# PIC18F55Q24 register map
Vendor: Microchip
Registers are 8-bit, read-write, reset 0x0 unless marked. A register's access mark holds for its fields unless they carry their own. Addresses are absolute, and some are shared; only a register's first bit layout is shown; [hi:lo] are bit positions.

## DOS_xxxx_Interrupts
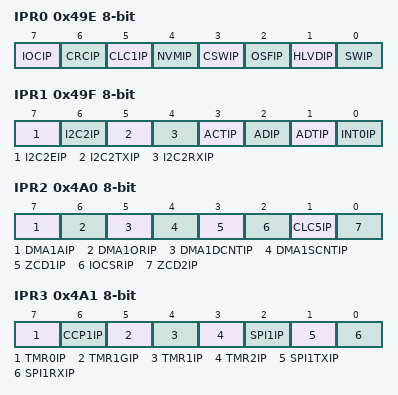
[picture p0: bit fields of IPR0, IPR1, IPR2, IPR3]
0x49E IPR0
  [7] IOCIP ro, [6] CRCIP, [5] CLC1IP, [4] NVMIP, [3] CSWIP, [2] OSFIP ro, [1] HLVDIP, [0] SWIP
0x49F IPR1
  [7] I2C2EIP, [6] I2C2IP, [5] I2C2TXIP, [4] I2C2RXIP, [3] ACTIP, [2] ADIP, [1] ADTIP, [0] INT0IP
0x4A0 IPR2
  [7] DMA1AIP, [6] DMA1ORIP, [5] DMA1DCNTIP, [4] DMA1SCNTIP, [3] ZCD1IP, [2] IOCSRIP, [1] CLC5IP, [0] ZCD2IP
0x4A1 IPR3
  [7] TMR0IP, [6] CCP1IP, [5] TMR1GIP, [4] TMR1IP, [3] TMR2IP, [2] SPI1IP ro, [1] SPI1TXIP ro, [0] SPI1RXIP ro
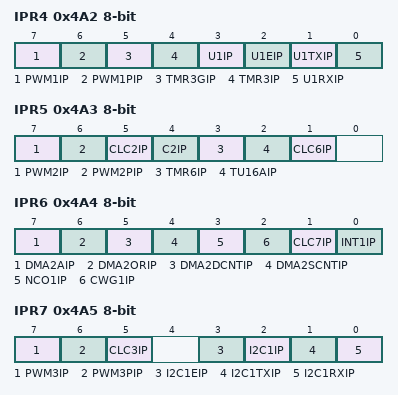
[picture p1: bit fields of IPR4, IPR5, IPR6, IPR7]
0x4A2 IPR4
  [7] PWM1IP, [6] PWM1PIP, [5] TMR3GIP, [4] TMR3IP, [3] U1IP ro, [2] U1EIP ro, [1] U1TXIP ro, [0] U1RXIP ro
0x4A3 IPR5
  [7] PWM2IP ro, [6] PWM2PIP, [5] CLC2IP, [4] C2IP, [3] TMR6IP, [2] TU16AIP ro, [1] CLC6IP
0x4A4 IPR6
  [7] DMA2AIP, [6] DMA2ORIP, [5] DMA2DCNTIP, [4] DMA2SCNTIP, [3] NCO1IP, [2] CWG1IP, [1] CLC7IP, [0] INT1IP
0x4A5 IPR7
  [7] PWM3IP ro, [6] PWM3PIP, [5] CLC3IP, [3] I2C1EIP ro, [2] I2C1IP ro, [1] I2C1TXIP ro, [0] I2C1RXIP ro
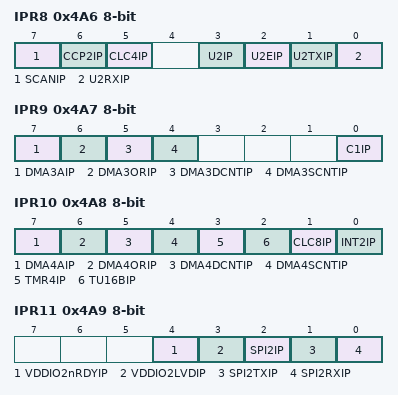
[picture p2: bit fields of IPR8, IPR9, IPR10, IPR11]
0x4A6 IPR8
  [7] SCANIP ro, [6] CCP2IP, [5] CLC4IP, [3] U2IP ro, [2] U2EIP ro, [1] U2TXIP ro, [0] U2RXIP ro
0x4A7 IPR9
  [7] DMA3AIP, [6] DMA3ORIP, [5] DMA3DCNTIP, [4] DMA3SCNTIP, [0] C1IP
0x4A8 IPR10
  [7] DMA4AIP, [6] DMA4ORIP, [5] DMA4DCNTIP, [4] DMA4SCNTIP, [3] TMR4IP, [2] TU16BIP ro, [1] CLC8IP, [0] INT2IP
0x4A9 IPR11
  [4] VDDIO2nRDYIP, [3] VDDIO2LVDIP, [2] SPI2IP ro, [1] SPI2TXIP ro, [0] SPI2RXIP ro
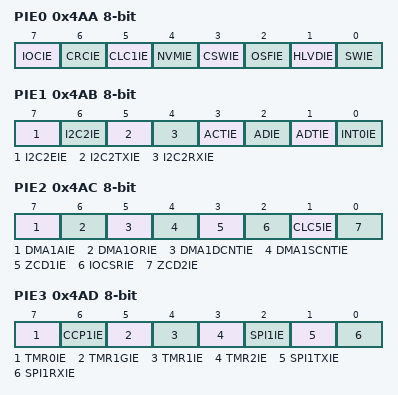
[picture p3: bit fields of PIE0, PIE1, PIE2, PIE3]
0x4AA PIE0
  [7] IOCIE ro, [6] CRCIE, [5] CLC1IE, [4] NVMIE, [3] CSWIE, [2] OSFIE ro, [1] HLVDIE, [0] SWIE
0x4AB PIE1
  [7] I2C2EIE, [6] I2C2IE, [5] I2C2TXIE, [4] I2C2RXIE, [3] ACTIE, [2] ADIE, [1] ADTIE, [0] INT0IE
0x4AC PIE2
  [7] DMA1AIE, [6] DMA1ORIE, [5] DMA1DCNTIE, [4] DMA1SCNTIE, [3] ZCD1IE, [2] IOCSRIE, [1] CLC5IE, [0] ZCD2IE
0x4AD PIE3
  [7] TMR0IE, [6] CCP1IE, [5] TMR1GIE, [4] TMR1IE, [3] TMR2IE, [2] SPI1IE ro, [1] SPI1TXIE ro, [0] SPI1RXIE ro
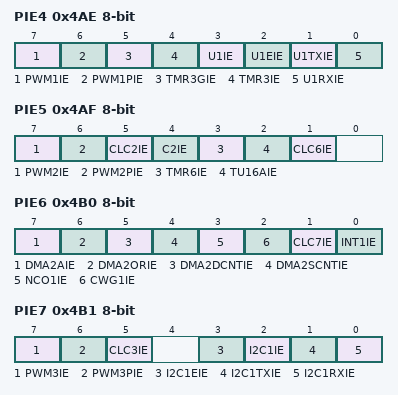
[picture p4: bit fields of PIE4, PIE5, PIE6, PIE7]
0x4AE PIE4
  [7] PWM1IE, [6] PWM1PIE, [5] TMR3GIE, [4] TMR3IE, [3] U1IE ro, [2] U1EIE ro, [1] U1TXIE ro, [0] U1RXIE ro
0x4AF PIE5
  [7] PWM2IE ro, [6] PWM2PIE, [5] CLC2IE, [4] C2IE, [3] TMR6IE, [2] TU16AIE ro, [1] CLC6IE
0x4B0 PIE6
  [7] DMA2AIE, [6] DMA2ORIE, [5] DMA2DCNTIE, [4] DMA2SCNTIE, [3] NCO1IE, [2] CWG1IE, [1] CLC7IE, [0] INT1IE
0x4B1 PIE7
  [7] PWM3IE ro, [6] PWM3PIE, [5] CLC3IE, [3] I2C1EIE ro, [2] I2C1IE ro, [1] I2C1TXIE ro, [0] I2C1RXIE ro
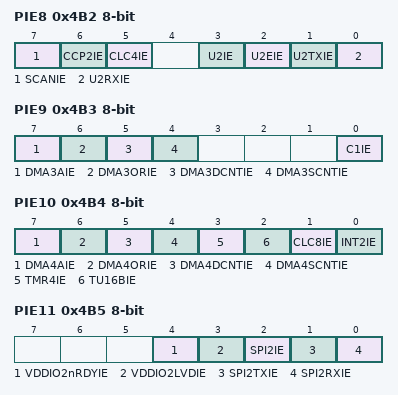
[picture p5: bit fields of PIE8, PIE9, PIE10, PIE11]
0x4B2 PIE8
  [7] SCANIE ro, [6] CCP2IE, [5] CLC4IE, [3] U2IE ro, [2] U2EIE ro, [1] U2TXIE ro, [0] U2RXIE ro
0x4B3 PIE9
  [7] DMA3AIE, [6] DMA3ORIE, [5] DMA3DCNTIE, [4] DMA3SCNTIE, [0] C1IE
0x4B4 PIE10
  [7] DMA4AIE, [6] DMA4ORIE, [5] DMA4DCNTIE, [4] DMA4SCNTIE, [3] TMR4IE, [2] TU16BIE ro, [1] CLC8IE, [0] INT2IE
0x4B5 PIE11
  [4] VDDIO2nRDYIE, [3] VDDIO2LVDIE, [2] SPI2IE ro, [1] SPI2TXIE ro, [0] SPI2RXIE ro
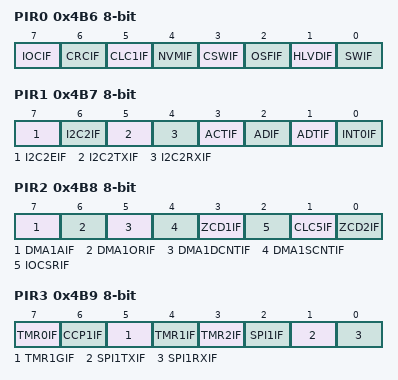
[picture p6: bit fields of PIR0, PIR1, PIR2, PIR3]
0x4B6 PIR0
  [7] IOCIF ro, [6] CRCIF, [5] CLC1IF, [4] NVMIF, [3] CSWIF, [2] OSFIF ro, [1] HLVDIF, [0] SWIF
0x4B7 PIR1
  [7] I2C2EIF, [6] I2C2IF, [5] I2C2TXIF, [4] I2C2RXIF, [3] ACTIF, [2] ADIF, [1] ADTIF, [0] INT0IF
0x4B8 PIR2
  [7] DMA1AIF, [6] DMA1ORIF, [5] DMA1DCNTIF, [4] DMA1SCNTIF, [3] ZCD1IF, [2] IOCSRIF, [1] CLC5IF, [0] ZCD2IF
0x4B9 PIR3
  [7] TMR0IF, [6] CCP1IF, [5] TMR1GIF, [4] TMR1IF, [3] TMR2IF, [2] SPI1IF ro, [1] SPI1TXIF ro, [0] SPI1RXIF ro
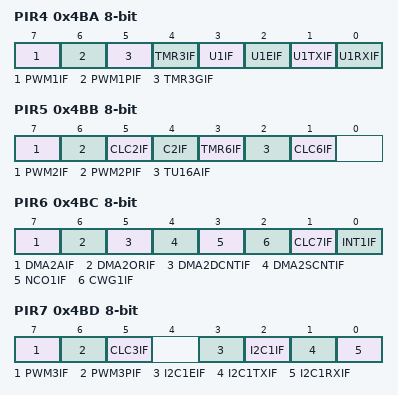
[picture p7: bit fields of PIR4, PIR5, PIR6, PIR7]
0x4BA PIR4
  [7] PWM1IF, [6] PWM1PIF, [5] TMR3GIF, [4] TMR3IF, [3] U1IF ro, [2] U1EIF ro, [1] U1TXIF ro, [0] U1RXIF ro
0x4BB PIR5
  [7] PWM2IF ro, [6] PWM2PIF, [5] CLC2IF, [4] C2IF, [3] TMR6IF, [2] TU16AIF ro, [1] CLC6IF
0x4BC PIR6
  [7] DMA2AIF, [6] DMA2ORIF, [5] DMA2DCNTIF, [4] DMA2SCNTIF, [3] NCO1IF, [2] CWG1IF, [1] CLC7IF, [0] INT1IF
0x4BD PIR7
  [7] PWM3IF ro, [6] PWM3PIF, [5] CLC3IF, [3] I2C1EIF ro, [2] I2C1IF ro, [1] I2C1TXIF ro, [0] I2C1RXIF ro
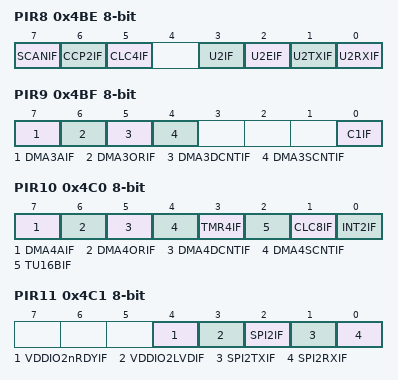
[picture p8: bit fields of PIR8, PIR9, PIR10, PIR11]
0x4BE PIR8
  [7] SCANIF ro, [6] CCP2IF, [5] CLC4IF, [3] U2IF ro, [2] U2EIF ro, [1] U2TXIF ro, [0] U2RXIF ro
0x4BF PIR9
  [7] DMA3AIF, [6] DMA3ORIF, [5] DMA3DCNTIF, [4] DMA3SCNTIF, [0] C1IF
0x4C0 PIR10
  [7] DMA4AIF, [6] DMA4ORIF, [5] DMA4DCNTIF, [4] DMA4SCNTIF, [3] TMR4IF, [2] TU16BIF ro, [1] CLC8IF, [0] INT2IF
0x4C1 PIR11
  [4] VDDIO2nRDYIF, [3] VDDIO2LVDIF, [2] SPI2IF ro, [1] SPI2TXIF ro, [0] SPI2RXIF ro
